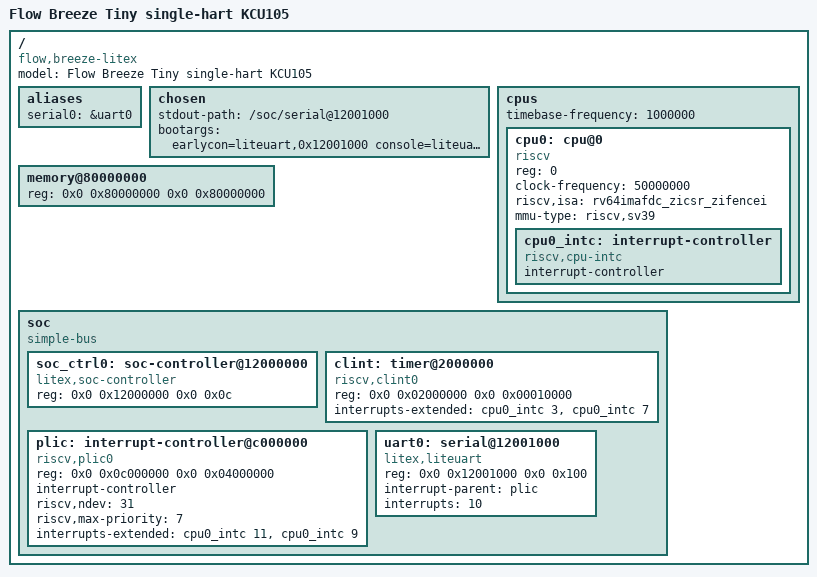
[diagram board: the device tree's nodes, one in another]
/dts-v1/;

/ {
	#address-cells = <2>;
	#size-cells = <2>;
	compatible = "flow,breeze-litex";
	model = "Flow Breeze Tiny single-hart KCU105";
	aliases {
		serial0 = &uart0;
	};

	chosen {
		stdout-path = "/soc/serial@12001000";
		bootargs = "earlycon=liteuart,0x12001000 console=liteuart";
	};

	cpus {
		#address-cells = <1>;
		#size-cells = <0>;
		timebase-frequency = <1000000>;

		cpu0: cpu@0 {
			device_type = "cpu";
			reg = <0>;
			clock-frequency = <50000000>;
			status = "okay";
			compatible = "riscv";
			riscv,isa = "rv64imafdc_zicsr_zifencei";
			mmu-type = "riscv,sv39";
			cpu0_intc: interrupt-controller {
				#address-cells = <0>;
				#interrupt-cells = <1>;
				interrupt-controller;
				compatible = "riscv,cpu-intc";
			};
		};

	};

	memory@80000000 {
		device_type = "memory";
		reg = <0x0 0x80000000 0x0 0x80000000>;
	};

	soc {
		#address-cells = <2>;
		#size-cells = <2>;
		compatible = "simple-bus";
		ranges;

		soc_ctrl0: soc-controller@12000000 {
			compatible = "litex,soc-controller";
			reg = <0x0 0x12000000 0x0 0x0c>;
			status = "okay";
		};

		clint: timer@2000000 {
			compatible = "riscv,clint0";
			reg = <0x0 0x02000000 0x0 0x00010000>;
			interrupts-extended = <
				&cpu0_intc 3 &cpu0_intc 7
			>;
		};

		plic: interrupt-controller@c000000 {
			#address-cells = <0>;
			compatible = "riscv,plic0";
			reg = <0x0 0x0c000000 0x0 0x04000000>;
			#interrupt-cells = <1>;
			interrupt-controller;
			riscv,ndev = <31>;
			riscv,max-priority = <7>;
			interrupts-extended = <
				&cpu0_intc 11 &cpu0_intc 9
			>;
		};

		uart0: serial@12001000 {
			compatible = "litex,liteuart";
			reg = <0x0 0x12001000 0x0 0x100>;
			interrupt-parent = <&plic>;
			interrupts = <10>;
			status = "okay";
		};
	};
};
